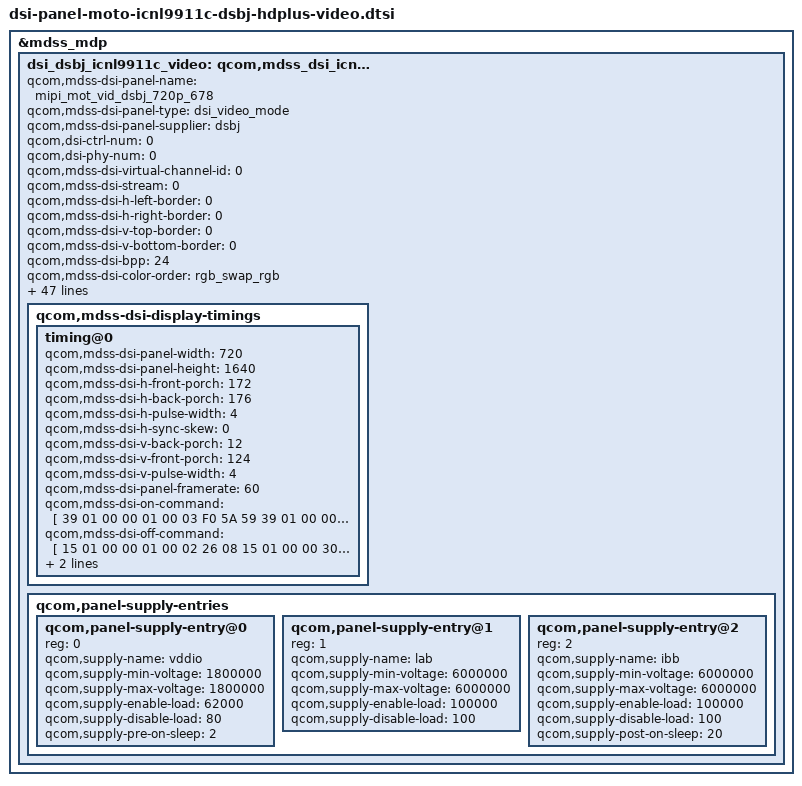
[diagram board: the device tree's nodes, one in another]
/* Copyright (c) 2020-2021, The Linux Foundation. All rights reserved.
 *
 * This program is free software; you can redistribute it and/or modify
 * it under the terms of the GNU General Public License version 2 and
 * only version 2 as published by the Free Software Foundation.
 *
 * This program is distributed in the hope that it will be useful,
 * but WITHOUT ANY WARRANTY; without even the implied warranty of
 * MERCHANTABILITY or FITNESS FOR A PARTICULAR PURPOSE.  See the
 * GNU General Public License for more details.
 */

/*---------------------------------------------------------------------------
 * This file is autogenerated file using gcdb parser. Please do not edit it.
 * Update input XML file to add a new entry or update variable in this file
 * VERSION = "1.0"
 *---------------------------------------------------------------------------
 */

&mdss_mdp {
	dsi_dsbj_icnl9911c_video:qcom,mdss_dsi_icnl9911c_dsbj_video {
		qcom,mdss-dsi-panel-name ="mipi_mot_vid_dsbj_720p_678";
		qcom,mdss-dsi-panel-type = "dsi_video_mode";
                qcom,mdss-dsi-panel-supplier = "dsbj";

		qcom,dsi-ctrl-num = <0>;
		qcom,dsi-phy-num = <0>;

		qcom,mdss-dsi-virtual-channel-id = <0>;
		qcom,mdss-dsi-stream = <0>;
		qcom,mdss-dsi-h-left-border = <0>;
		qcom,mdss-dsi-h-right-border = <0>;
		qcom,mdss-dsi-v-top-border = <0>;
		qcom,mdss-dsi-v-bottom-border = <0>;
		qcom,mdss-dsi-bpp = <24>;
		qcom,mdss-dsi-color-order = "rgb_swap_rgb";
		qcom,mdss-dsi-underflow-color = <0xff>;
		qcom,mdss-dsi-border-color = <0>;
		qcom,mdss-dsi-h-sync-pulse = <0>;
		qcom,mdss-dsi-traffic-mode = "non_burst_sync_event";
		qcom,mdss-dsi-lane-map = "lane_map_0123";
		qcom,mdss-dsi-bllp-eof-power-mode;
		qcom,mdss-dsi-bllp-power-mode;
		qcom,mdss-dsi-tx-eot-append;
		qcom,mdss-dsi-lane-0-state;
		qcom,mdss-dsi-lane-1-state;
		qcom,mdss-dsi-lane-2-state;
		qcom,mdss-dsi-lane-3-state;
		qcom,mdss-dsi-dma-trigger = "trigger_sw";
		qcom,mdss-dsi-mdp-trigger = "none";
		qcom,mdss-dsi-lp11-init;
		qcom,suspend-ulps-enabled;
		qcom,platform-reset-gpio-always-on;
		qcom,mdss-panel-on-rst-pull-down;
		qcom,mdss-dsi-reset-sequence = <1 10>, <0 10>, <1 30>;
		qcom,mdss-pan-physical-width-dimension = <69>;
		qcom,mdss-pan-physical-height-dimension = <158>;

		qcom,mdss-dsi-bl-pmic-control-type = "bl_ctrl_wled";
		qcom,mdss-dsi-bl-min-level = <1>;
		qcom,mdss-dsi-bl-max-level = <2047>;
		qcom,mdss-dsi-bl-default-level = <127>;

		qcom,mdss-dsi-cabc-ui-command = [
			15 01 00 00 00 00 02 55 01
			39 01 00 00 00 00 03 F0 5A 59
			39 01 00 00 00 00 03 F1 A5 A6
			39 01 00 00 00 00 18 E1 EF FE FE FE FE EE F0 20 33 FF 00 00 6A 90 C0 0D 6A F0 3E FF 00 0E 83
			39 01 00 00 00 00 1B E0 30 00 80 88 11 3F 22 62 DF A0 04 CC 01 FF F6 FF F0 FD FF FD F8 F5 FC FC FD FF
			39 01 00 00 00 00 03 F1 5A 59
			39 01 00 00 00 00 03 F0 A5 A6
		];
		qcom,mdss-dsi-cabc-ui-command-state = "dsi_hs_mode";
		qcom,mdss-dsi-cabc-mv-command = [
			15 01 00 00 00 00 02 55 03
			39 01 00 00 00 00 03 F0 5A 59
			39 01 00 00 00 00 03 F1 A5 A6
			39 01 00 00 00 00 18 E1 BC F8 CC FA DB 9B F0 E7 F0 85 F0 70 00 50 00 9A FD F0 E0 FF 00 0E 83
			39 01 00 00 00 00 1B E0 30 00 80 88 11 3F 22 62 DF A0 04 CC 01 FF FA FF F0 FD FF FB F8 F5 FC FC FB FF
			39 01 00 00 00 00 03 F1 5A 59
			39 01 00 00 00 00 03 F0 A5 A6
		];
		qcom,mdss-dsi-cabc-mv-command-state = "dsi_hs_mode";
		qcom,mdss-dsi-cabc-dis-command = [15 01 00 00 00 00 02 55 00];
		qcom,mdss-dsi-cabc-dis-command-state = "dsi_hs_mode";
		qcom,mdss-dsi-hbm-on-command = [39 01 00 00 00 00 03 51 0F FF];
		qcom,mdss-dsi-hbm-on-command-state = "dsi_hs_mode";
		qcom,mdss-dsi-hbm-off-command = [39 01 00 00 00 00 03 51 0C CC];
		qcom,mdss-dsi-hbm-off-command-state = "dsi_hs_mode";

		qcom,mdss-dsi-display-timings {
			timing@0{
				qcom,mdss-dsi-panel-width = <720>;
				qcom,mdss-dsi-panel-height = <1640>;
				qcom,mdss-dsi-h-front-porch = <172>;
				qcom,mdss-dsi-h-back-porch = <176>;
				qcom,mdss-dsi-h-pulse-width = <4>;
				qcom,mdss-dsi-h-sync-skew = <0>;
				qcom,mdss-dsi-v-back-porch = <12>;
				qcom,mdss-dsi-v-front-porch = <124>;
				qcom,mdss-dsi-v-pulse-width = <4>;
				qcom,mdss-dsi-panel-framerate = <60>;
				qcom,mdss-dsi-on-command = [
					39 01 00 00 01 00 03 F0 5A 59
					39 01 00 00 01 00 03 F1 A5 A6
					39 01 00 00 01 00 09 C1 C0 0C 20 7C 04 B0 AC 04
					39 01 00 00 01 00 03 F1 5A 59
					39 01 00 00 01 00 03 F0 A5 A6
					05 01 00 00 00 00 02 35 00
					39 01 00 00 00 00 03 51 0C CC
					15 01 00 00 00 00 02 53 2C
					15 01 00 00 00 00 02 55 01
					39 01 00 00 00 00 03 F0 5A 59
					39 01 00 00 00 00 03 F1 A5 A6
					39 01 00 00 00 00 18 E1 EF FE FE FE FE EE F0 20 33 FF 00 00 6A 90 C0 0D 6A F0 3E FF 00 0E 83
					39 01 00 00 00 00 1B E0 30 00 80 88 11 3F 22 62 DF A0 04 CC 01 FF F6 FF F0 FD FF FD F8 F5 FC FC FD FF
					39 01 00 00 00 00 03 F1 5A 59
					39 01 00 00 00 00 03 F0 A5 A6
					05 01 00 00 50 00 02 11 00
					05 01 00 00 35 00 02 29 00
					39 01 00 00 00 00 02 26 01];
				qcom,mdss-dsi-off-command = [
					15 01 00 00 01 00 02 26 08
					15 01 00 00 30 00 02 28 00
					15 01 00 00 78 00 02 10 00
					];
				qcom,mdss-dsi-on-command-state = "dsi_lp_mode";
				qcom,mdss-dsi-off-command-state = "dsi_lp_mode";
			};
		};

		qcom,panel-supply-entries {
			#address-cells = <1>;
			#size-cells = <0>;

			qcom,panel-supply-entry@0 {
				reg = <0>;
				qcom,supply-name = "vddio";
				qcom,supply-min-voltage = <1800000>;
				qcom,supply-max-voltage = <1800000>;
				qcom,supply-enable-load = <62000>;
				qcom,supply-disable-load = <80>;
				qcom,supply-pre-on-sleep = <2>;
			};

			qcom,panel-supply-entry@1 {
				reg = <1>;
				qcom,supply-name = "lab";
				qcom,supply-min-voltage = <6000000>;
				qcom,supply-max-voltage = <6000000>;
				qcom,supply-enable-load = <100000>;
				qcom,supply-disable-load = <100>;
			};

			qcom,panel-supply-entry@2 {
				reg = <2>;
				qcom,supply-name = "ibb";
				qcom,supply-min-voltage = <6000000>;
				qcom,supply-max-voltage = <6000000>;
				qcom,supply-enable-load = <100000>;
				qcom,supply-disable-load = <100>;
				qcom,supply-post-on-sleep = <20>;
			};
		};
	};
};

